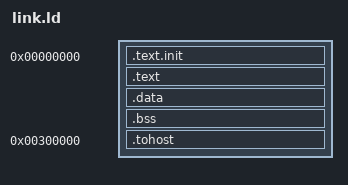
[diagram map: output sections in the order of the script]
OUTPUT_ARCH( "riscv" )
ENTRY(_start)

SECTIONS
{
  . = 0x0;
  .text.init : { *(.text.init) }
  .text : { *(.text) }
  .data : { *(.data) }
  .bss : { *(.bss) }
  _end = .;
  . = 0x300000;
  .tohost : { *(.tohost) }
}
